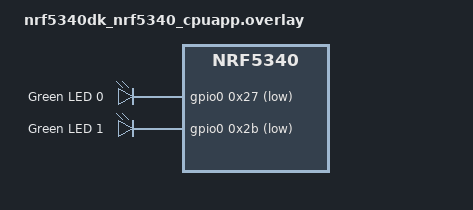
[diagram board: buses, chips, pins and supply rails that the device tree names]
/{
	leds {
		compatible = "gpio-leds";
		led0: led_0 {
			gpios = < &gpio0 0x27 0x1 >;
			label = "Green LED 0";
		};
		led1: led_1 {
			gpios = < &gpio0 0x2b 0x1 >;
			label = "Green LED 1";
		};
	};
};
